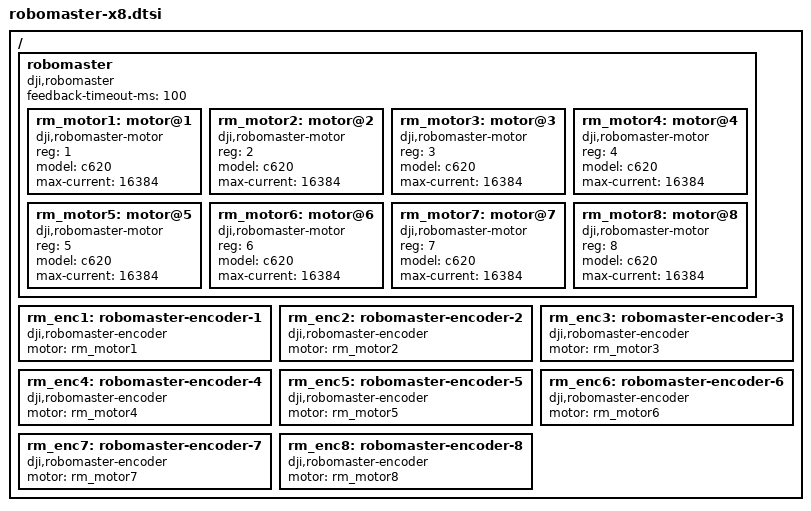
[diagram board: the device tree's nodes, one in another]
/*
 * Copyright (c) 2026
 * SPDX-License-Identifier: Apache-2.0
 *
 * Every RoboMaster ESC a dji,robomaster transport can address (ids 1..8),
 * each with its rotor angle as an encoder. Board independent: the board's
 * fragment includes this and says which CAN controllers carry the bus.
 *
 *     #include <fibril/robomaster-x8.dtsi>
 *
 *     &robomaster {
 *         cans = <&fdcan2 &fdcan3>;
 *     };
 *
 * All eight are always defined, fitted or not. A motor that is not fitted
 * never reports, which reads as no feedback on its motor and no data on its
 * encoder; nothing waits for it and nothing else is affected. So a
 * deployment picks motors by naming them in its fibril,fcan-* node, never by
 * adding or removing them here.
 *
 * Every ESC is a C620 at its full command range. A deployment that fits a
 * C610 or lowers a limit overrides the one motor:
 *
 *     &rm_motor3 {
 *         model = "c610";
 *     };
 */

#ifndef FIBRIL_ROBOMASTER_X8_DTSI
#define FIBRIL_ROBOMASTER_X8_DTSI

/ {
    robomaster: robomaster {
        compatible = "dji,robomaster";
        #address-cells = <1>;
        #size-cells = <0>;

        /* RoboMaster ESCs report every 1 ms, so this is many missed frames
         * before a motor reads as stale. It is also the gap after which a
         * rotor encoder starts its position over. */
        feedback-timeout-ms = <100>;

        /* duty-full-scale on the md_motor node, not this limit, decides what
         * a duty of 1.0 means. */
        rm_motor1: motor@1 {
            compatible = "dji,robomaster-motor";
            reg = <1>;
            model = "c620";
            max-current = <16384>;
        };

        rm_motor2: motor@2 {
            compatible = "dji,robomaster-motor";
            reg = <2>;
            model = "c620";
            max-current = <16384>;
        };

        rm_motor3: motor@3 {
            compatible = "dji,robomaster-motor";
            reg = <3>;
            model = "c620";
            max-current = <16384>;
        };

        rm_motor4: motor@4 {
            compatible = "dji,robomaster-motor";
            reg = <4>;
            model = "c620";
            max-current = <16384>;
        };

        rm_motor5: motor@5 {
            compatible = "dji,robomaster-motor";
            reg = <5>;
            model = "c620";
            max-current = <16384>;
        };

        rm_motor6: motor@6 {
            compatible = "dji,robomaster-motor";
            reg = <6>;
            model = "c620";
            max-current = <16384>;
        };

        rm_motor7: motor@7 {
            compatible = "dji,robomaster-motor";
            reg = <7>;
            model = "c620";
            max-current = <16384>;
        };

        rm_motor8: motor@8 {
            compatible = "dji,robomaster-motor";
            reg = <8>;
            model = "c620";
            max-current = <16384>;
        };
    };

    /* Rotor counts, 8192 per rotor turn before the gearbox, so encoder/gain
     * on the ROS side has to carry the gear ratio. */
    rm_enc1: robomaster-encoder-1 {
        compatible = "dji,robomaster-encoder";
        motor = <&rm_motor1>;
    };

    rm_enc2: robomaster-encoder-2 {
        compatible = "dji,robomaster-encoder";
        motor = <&rm_motor2>;
    };

    rm_enc3: robomaster-encoder-3 {
        compatible = "dji,robomaster-encoder";
        motor = <&rm_motor3>;
    };

    rm_enc4: robomaster-encoder-4 {
        compatible = "dji,robomaster-encoder";
        motor = <&rm_motor4>;
    };

    rm_enc5: robomaster-encoder-5 {
        compatible = "dji,robomaster-encoder";
        motor = <&rm_motor5>;
    };

    rm_enc6: robomaster-encoder-6 {
        compatible = "dji,robomaster-encoder";
        motor = <&rm_motor6>;
    };

    rm_enc7: robomaster-encoder-7 {
        compatible = "dji,robomaster-encoder";
        motor = <&rm_motor7>;
    };

    rm_enc8: robomaster-encoder-8 {
        compatible = "dji,robomaster-encoder";
        motor = <&rm_motor8>;
    };
};

#endif /* FIBRIL_ROBOMASTER_X8_DTSI */
